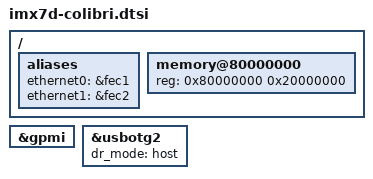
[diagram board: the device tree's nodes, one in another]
// SPDX-License-Identifier: GPL-2.0+ OR MIT
/*
 * Copyright 2016-2021 Toradex
 */

#include "imx7d.dtsi"
#include "imx7-colibri.dtsi"

/ {
	aliases {
		/* add ethernet aliases which is required to proprely pass mac
		   address from bootloader. Also with the update to 5.4.70-2.3.0
		   the kernel hangs without these aliases.
		 */
		ethernet0 = &fec1;
		ethernet1 = &fec2;
	};

	memory@80000000 {
		device_type = "memory";
		reg = <0x80000000 0x20000000>;
	};
};

&gpmi {
	status = "okay";
};

&usbotg2 {
	dr_mode = "host";
};
